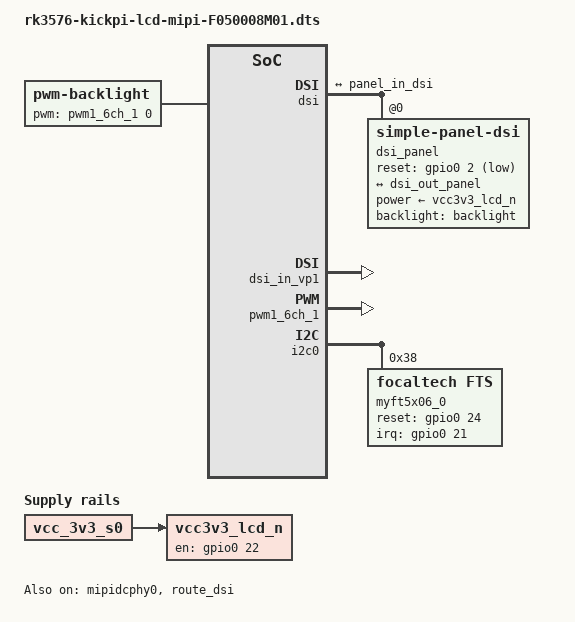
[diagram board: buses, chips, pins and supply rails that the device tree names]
/dts-v1/;
/plugin/;

/ {
    fragment@0 {
        target-path = "/";
        __overlay__ {
            backlight: backlight {
                compatible = "pwm-backlight";
                pwms = <&pwm1_6ch_1 0 25000 0>;
                brightness-levels = <
                    0  20  20  21  21  22  22  23
                    23  24  24  25  25  26  26  27
                    27  28  28  29  29  30  30  31
                    31  32  32  33  33  34  34  35
                    35  36  36  37  37  38  38  39
                    40  41  42  43  44  45  46  47
                    48  49  50  51  52  53  54  55
                    56  57  58  59  60  61  62  63
                    64  65  66  67  68  69  70  71
                    72  73  74  75  76  77  78  79
                    80  81  82  83  84  85  86  87
                    88  89  90  91  92  93  94  95
                    96  97  98  99 100 101 102 103
                    104 105 106 107 108 109 110 111
                    112 113 114 115 116 117 118 119
                    120 121 122 123 124 125 126 127
                    128 129 130 131 132 133 134 135
                    136 137 138 139 140 141 142 143
                    144 145 146 147 148 149 150 151
                    152 153 154 155 156 157 158 159
                    160 161 162 163 164 165 166 167
                    168 169 170 171 172 173 174 175
                    176 177 178 179 180 181 182 183
                    184 185 186 187 188 189 190 191
                    192 193 194 195 196 197 198 199
                    200 201 202 203 204 205 206 207
                    208 209 210 211 212 213 214 215
                    216 217 218 219 220 221 222 223
                    224 225 226 227 228 229 230 231
                    232 233 234 235 236 237 238 239
                    240 241 242 243 244 245 246 247
                    248 249 250 251 252 253 254 255
                >;
                default-brightness-level = <200>;
            };

            vcc3v3_lcd_n: vcc3v3-lcd0-n {
                compatible = "regulator-fixed";
                regulator-name = "vcc3v3_lcd0_n";
                regulator-boot-on;
                enable-active-high;
                gpio = <&gpio0 22 0>;
                vin-supply = <&vcc_3v3_s0>;
            };
        };
    };

    fragment@1 {
        target = <&dsi>;
        __overlay__ {
            status = "okay";
            #address-cells = <1>;
            #size-cells = <0>;
            dsi_panel: panel@0 {
                status = "okay";
                
                compatible = "simple-panel-dsi";
                reg = <0>;
                backlight = <&backlight>;
                power-supply = <&vcc3v3_lcd_n>;

                reset-gpios = <&gpio0 2 1>;

                reset-delay-ms = <120>;
                enable-delay-ms = <120>;
                prepare-delay-ms = <120>;
                init-delay-ms = <120>;
                unprepare-delay-ms = <60>;
                disable-delay-ms = <60>;
                
                width-mm = <68>;
                height-mm = <121>;
                
                dsi,flags = <((1 << 0) | (1 << 1) |
                        (1 << 11) | (1 << 9))>;
                dsi,format = <0>;
                dsi,lanes  = <4>;
                
                panel-init-sequence = [
                    // CMD2 ENABLE
                    15 00 02 00 00
                    39 00 04 FF 87 56 01
                    15 00 02 00 80
                    39 00 03 FF 87 56
                    // Panel Resolution 720x1280
                    15 00 02 00 A1
                    39 00 07 B3 02 D0 05 00 20 FC
                    // TCON
                    15 00 02 00 80
                    39 00 07 C0 00 F6 00 10 00 24
                    15 00 02 00 90
                    39 00 07 C0 00 F6 00 10 00 24
                    15 00 02 00 A0
                    39 00 07 C0 02 14 00 10 00 24
                    15 00 02 00 B0
                    39 00 07 C0 00 F6 00 10 00 24
                    15 00 02 00 C1
                    39 00 09 C0 01 27 00 EA 00 C5 01 5F
                    15 00 02 00 D7
                    39 00 07 C0 00 C5 00 10 00 24
                    15 00 02 00 A3
                    39 00 07 C1 00 20 00 20 00 02
                    15 00 02 00 80
                    39 00 11 CE 01 81 09 13 00 78 00 78 00 50 00 50 00 78 00 78
                    15 00 02 00 90
                    39 00 10 CE 00 8E 0E B6 00 8E 80 09 13 00 04 00 1C 1F 16
                    15 00 02 00 A0
                    39 00 04 CE 20 00 00
                    15 00 02 00 B0
                    39 00 04 CE 22 00 00
                    15 00 02 00 D1
                    39 00 08 CE 00 00 01 00 00 00 00
                    15 00 02 00 E1
                    39 00 0C CE 08 02 4D 02 4D 02 4D 00 00 00 00
                    15 00 02 00 F1
                    39 00 0A CE 0C 06 0A 00 E9 00 E9 00 F8
                    15 00 02 00 B0
                    39 00 05 CF 00 00 6E 72
                    15 00 02 00 B5
                    39 00 05 CF 02 02 94 98
                    15 00 02 00 C0
                    39 00 05 CF 04 04 D8 DC
                    15 00 02 00 C5
                    39 00 05 CF 00 00 08 0C
                    // Scan Mode
                    15 00 02 00 E8
                    15 00 02 C0 40
                    // VST1&VST2
                    15 00 02 00 80
                    39 00 09 C2 84 00 05 89 83 00 05 89
                    // CKV1-3
                    15 00 02 00 A0
                    39 00 10 C2 82 04 00 05 89 81 04 00 05 89 00 04 00 05 89
                    // CKV4-6
                    15 00 02 00 B0
                    39 00 10 C2 01 04 00 05 89 02 04 00 05 89 03 04 00 05 89
                    // CKV7-8
                    15 00 02 00 C0
                    39 00 0B C2 04 04 00 05 89 05 04 00 05 89
                    15 00 02 00 E0
                    39 00 05 C2 77 77 77 77
                    15 00 02 00 C0
                    39 00 05 C3 99 99 99 99
                    15 00 02 00 80
                    39 00 11 CB 00 C5 00 00 05 05 00 05 0A 05 C5 00 05 05 00 C0
                    15 00 02 00 90
                    39 00 11 CB 00 00 00 00 00 00 00 00 00 00 00 00 00 00 00 00
                    15 00 02 00 A0
                    39 00 05 CB 00 00 00 00
                    15 00 02 00 B0
                    39 00 05 CB 10 51 94 50
                    15 00 02 00 C0
                    39 00 05 CB 10 51 94 50
                    15 00 02 00 80
                    39 00 11 CC 2D 2D 2D 2D 07 09 0B 0D 25 25 03 2D 22 2D 24 2D
                    15 00 02 00 90
                    39 00 09 CC 29 16 17 18 19 1A 1B 26
                    15 00 02 00 80
                    39 00 11 CD 2D 2D 2D 2D 06 08 0A 0C 25 00 02 2D 22 2D 24 2D
                    15 00 02 00 90
                    39 00 09 CD 29 16 17 18 19 1A 1B 26
                    15 00 02 00 A0
                    39 00 11 CC 2D 2D 2D 2D 08 06 0C 0A 25 25 02 2D 24 2D 23 2D
                    15 00 02 00 B0
                    39 00 09 CC 29 16 17 18 19 1A 1B 26
                    15 00 02 00 A0
                    39 00 11 CD 2D 2D 2D 2D 09 07 0D 0B 25 00 03 2D 24 2D 23 2D
                    15 00 02 00 B0
                    39 00 09 CD 29 16 17 18 19 1A 1B 26
                    15 00 02 00 80
                    15 00 02 A7 13 //0x13  RGBBGR  0x16  RGBRGB
                    15 00 02 00 82
                    39 00 03 A7 22 02
                    15 00 02 00 85
                    15 00 02 C4 1C
                    15 00 02 00 A0
                    39 00 04 C4 8D D8 8D
                    15 00 02 00 93
                    15 00 02 C5 37
                    15 00 02 00 97
                    15 00 02 C5 37
                    15 00 02 00 B6
                    39 00 03 C5 2D 2D
                    15 00 02 00 9A
                    15 00 02 C5 19
                    15 00 02 00 9C
                    15 00 02 C5 19
                    15 00 02 00 97
                    15 00 02 C4 01
                    15 00 02 00 9B
                    15 00 02 F5 4B
                    15 00 02 00 93
                    39 00 03 F5 00 00
                    15 00 02 00 9D
                    15 00 02 F5 49
                    15 00 02 00 82
                    39 00 03 F5 00 00
                    15 00 02 00 8C
                    39 00 04 C3 00 00 00
                    15 00 02 00 84
                    39 00 03 C5 28 28
                    15 00 02 00 A4
                    15 00 02 D7 00
                    15 00 02 00 80
                    39 00 03 F5 59 59
                    15 00 02 00 84
                    39 00 04 F5 59 59 59
                    15 00 02 00 96
                    15 00 02 F5 59
                    15 00 02 00 A6
                    15 00 02 F5 59
                    15 00 02 00 CA
                    15 00 02 C0 80
                    15 00 02 00 B1
                    15 00 02 F5 1F
                    15 00 02 00 00
                    39 00 03 D8 29 2D
                    15 00 02 00 86
                    39 00 07 C0 01 04 01 01 22 03
                    15 00 02 00 96
                    39 00 07 C0 01 04 01 01 1B 03
                    15 00 02 00 A6
                    39 00 07 C0 01 04 01 01 3E 03
                    15 00 02 00 E9
                    39 00 07 C0 01 04 01 01 1B 03
                    15 00 02 00 A3
                    39 00 07 CE 01 04 01 01 1B 03
                    15 00 02 00 B3
                    39 00 07 CE 01 04 01 01 1B 03
                    // gamma2.2
                    15 00 02 00 00
                    39 00 29 E1 05 06 09 10 69 1A 22 28 33 98 3A 41 47 4C E5 51 59 60 67 05 6E 75 7C 85 08 8F 94 9B A2 22 AB B6 C4 CE 9E DA EA F7 FF 7B
                    15 00 02 00 00
                    39 00 29 E2 05 06 09 10 69 1A 22 28 33 98 3A 41 47 4C E5 51 59 60 67 05 6E 75 7C 85 08 8F 94 9B A2 22 AB B6 C4 CE 9E DA EA F7 FF 7B
                    15 00 02 00 00
                    39 00 29 E3 05 06 09 10 69 1A 22 28 33 98 3A 41 47 4C E5 51 59 60 67 05 6E 75 7C 85 08 8F 94 9B A2 22 AB B6 C4 CE 9E DA EA F7 FF 7B
                    15 00 02 00 00
                    39 00 29 E4 05 06 09 10 69 1A 22 28 33 98 3A 41 47 4C E5 51 59 60 67 05 6E 75 7C 85 08 8F 94 9B A2 22 AB B6 C4 CE 9E DA EA F7 FF 7B
                    15 00 02 00 00
                    39 00 29 E5 05 06 09 10 69 1A 22 28 33 98 3A 41 47 4C E5 51 59 60 67 05 6E 75 7C 85 08 8F 94 9B A2 22 AB B6 C4 CE 9E DA EA F7 FF 7B
                    15 00 02 00 00
                    39 00 29 E6 05 06 09 10 69 1A 22 28 33 98 3A 41 47 4C E5 51 59 60 67 05 6E 75 7C 85 08 8F 94 9B A2 22 AB B6 C4 CE 9E DA EA F7 FF 7B
                    // EN GND 4 frame
                    15 00 02 00 CC
                    15 00 02 C0 13
                    // LVD detect Voltage
                    15 00 02 00 82
                    15 00 02 C5 35
                    15 00 02 00 94
                    39 00 04 C5 02 01 01
                    15 00 02 00 98
                    39 00 03 C5 25 01
                    15 00 02 00 9B
                    15 00 02 C5 21
                    15 00 02 00 9D
                    15 00 02 C5 25
                    // Write ID
                    15 00 02 00 D0
                    15 00 02 D0 56
                    //LCD initial code End
                    05 78 01 11
                    05 00 01 29
                    15 00 02 35 00
                ];

                panel-exit-sequence = [
                    05 00 01 28
                    05 00 01 10
                ];

                disp_timings0: display-timings {
                    native-mode = <&dsi_timing0>;
                    dsi_timing0: timing0 {
                        clock-frequency = <84000000>;
                        hactive = <720>;
                        vactive = <1280>;
                        hfront-porch = <32>;
                        hsync-len = <15>;
                        hback-porch = <32>;
                        vfront-porch = <21>;
                        vsync-len = <15>;
                        vback-porch = <12>;
                        hsync-active = <0>;
                        vsync-active = <0>;
                        de-active = <0>;
                        pixelclk-active = <0>;
                    };
                };

                ports {
                    #address-cells = <1>;
                    #size-cells = <0>;

                    port@0 {
                        reg = <0>;
                        panel_in_dsi: endpoint {
                            remote-endpoint = <&dsi_out_panel>;
                        };
                    };
                };
            };

            ports {
                #address-cells = <1>;
                #size-cells = <0>;

                port@1 {
                    reg = <1>;
                    dsi_out_panel: endpoint {
                        remote-endpoint = <&panel_in_dsi>;
                    };
                };
            };
        };
    };

    fragment@2 {
        target = <&dsi_in_vp1>;
        __overlay__ {
            status = "okay";
        };
    };

    fragment@3 {
        target = <&mipidcphy0>;
        __overlay__ {
            status = "okay";
        };
    };

    fragment@4 {
        target = <&pwm1_6ch_1>;
        __overlay__ {
            status = "okay";
            pinctrl-0 = <&pwm1m0_ch1>;
        };
    };

    fragment@5 {
        target = <&route_dsi>;
        __overlay__ {
            status = "okay";
            connect = <&vp1_out_dsi>;
        };
    };

    fragment@6 {
        target = <&i2c0>;
        __overlay__ {
            pinctrl-0 = <&i2c0m1_xfer>;
            status = "okay";
            #address-cells = <1>;
            #size-cells = <0>;
            gt9xx1: gt9xx@14 {
                status = "disabled";
                compatible = "goodix,gt911";
                reg = <0x14>;
                pinctrl-names = "default";
                pinctrl-0 = <&touch1_gpio>;

                interrupt-parent = <&gpio0>;
                interrupts = <21 8>;

                irq-gpios =  <&gpio0 21 8>;
                reset-gpios = <&gpio0 24 0>;
                touchscreen-size-x = <800>;
                touchscreen-size-y = <1280>;
            };

            myft5x06_0: my-ft5x06@38 {
                compatible = "focaltech,fts";
                reg = <0x38>; 
                status = "okay";
        
                focaltech,reset-gpio = <&gpio0 24 0>;
                focaltech,irq-gpio = <&gpio0 21 8>; 
        
                pinctrl-names = "default";
                pinctrl-0 = <&touch1_gpio>;

                focaltech,display-coords = <0 0 720 1280>;
                focaltech,max-touch-number = <10>;
        
            };
        };
    };

    fragment@7 {
        target = <&pinctrl>;
        __overlay__ {
            touch1 {
                touch1_gpio: touch-gpio {
                    rockchip,pins =
                        <0 21 0 &pcfg_pull_up>,
                        <0 24 0 &pcfg_pull_none>;
                };
            };
        };
    };

};
